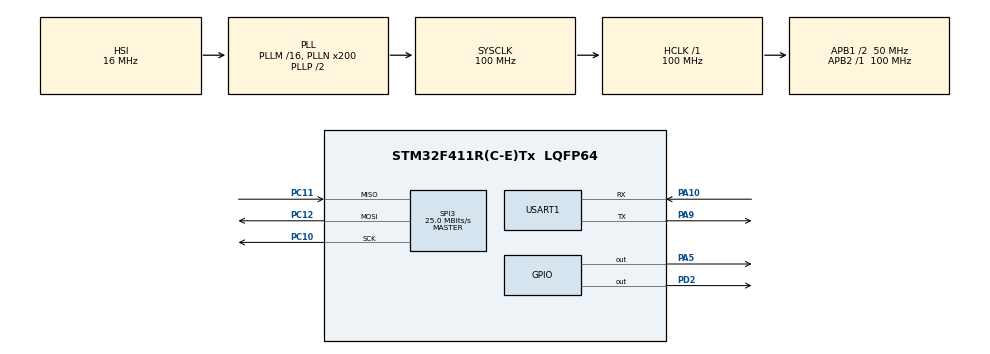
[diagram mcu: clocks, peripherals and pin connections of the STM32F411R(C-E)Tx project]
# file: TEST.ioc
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Mcu.Family=STM32F4
Mcu.Name=STM32F411R(C-E)Tx
Mcu.Package=LQFP64
NVIC.PriorityGroup=NVIC_PRIORITYGROUP_4
PA10.Mode=Asynchronous
PA10.Signal=USART1_RX
PA5.Signal=GPIO_Output
PA9.Mode=Asynchronous
PA9.Signal=USART1_TX
PC10.Mode=Full_Duplex_Master
PC10.Signal=SPI3_SCK
PC11.Mode=Full_Duplex_Master
PC11.Signal=SPI3_MISO
PC12.Mode=Full_Duplex_Master
PC12.Signal=SPI3_MOSI
PD2.PinState=GPIO_PIN_SET
PD2.Signal=GPIO_Output
ProjectManager.HeapSize=0x200
ProjectManager.StackSize=0x400
ProjectManager.TargetToolchain=Makefile
RCC.48MHZClocksFreq_Value=50000000
RCC.AHBFreq_Value=100000000
RCC.APB1CLKDivider=RCC_HCLK_DIV2
RCC.APB1Freq_Value=50000000
RCC.APB1TimFreq_Value=100000000
RCC.APB2Freq_Value=100000000
RCC.APB2TimFreq_Value=100000000
RCC.CortexFreq_Value=100000000
RCC.HCLKFreq_Value=100000000
RCC.HSE_VALUE=25000000
RCC.HSI_VALUE=16000000
RCC.LSE_VALUE=32768
RCC.PLLN=200
RCC.SYSCLKFreq_VALUE=100000000
RCC.SYSCLKSource=RCC_SYSCLKSOURCE_PLLCLK
RCC.VCOOutputFreq_Value=200000000
SPI3.BaudRatePrescaler=SPI_BAUDRATEPRESCALER_2
SPI3.CalculateBaudRate=25.0 MBits/s
SPI3.Direction=SPI_DIRECTION_2LINES
SPI3.Mode=SPI_MODE_MASTER
SPI3.VirtualType=VM_MASTER
USART1.VirtualMode=VM_ASYNC
VP_CRC_VS_CRC.Mode=CRC_Activate
board=custom

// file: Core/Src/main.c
/* USER CODE BEGIN Header */
/**
  ******************************************************************************
  * @file           : main.c
  * @brief          : Main program body
  ******************************************************************************
  * @attention
  *
  * Copyright (c) 2024 STMicroelectronics.
  * All rights reserved.
  *
  * This software is licensed under terms that can be found in the LICENSE file
  * in the root directory of this software component.
  * If no LICENSE file comes with this software, it is provided AS-IS.
  *
  ******************************************************************************
  */
/* USER CODE END Header */
#include "main.h"

/* USER CODE BEGIN PD */
#define MAJOR 0
#define MINOR 1

const uint8_t APP_VERSION[2]={MAJOR,MINOR};
/* USER CODE END PD */

CRC_HandleTypeDef hcrc;

SPI_HandleTypeDef hspi3;

UART_HandleTypeDef huart1;

void SystemClock_Config(void);
static void MX_GPIO_Init(void);
static void MX_CRC_Init(void);
static void MX_SPI3_Init(void);
static void MX_USART1_UART_Init(void);

int main(void)
{

  /* MCU Configuration--------------------------------------------------------*/

  /* Reset of all peripherals, Initializes the Flash interface and the Systick. */
  HAL_Init();

  /* Configure the system clock */
  SystemClock_Config();

  /* Initialize all configured peripherals */
  MX_GPIO_Init();
  MX_CRC_Init();
  MX_SPI3_Init();
  MX_USART1_UART_Init();

  /* Infinite loop */
  while (1)
  {
   HAL_GPIO_WritePin(GPIOA,GPIO_PIN_5,GPIO_PIN_SET); //LED ON
   HAL_Delay(50); //DELAY
   HAL_GPIO_WritePin(GPIOA,GPIO_PIN_5,GPIO_PIN_RESET); //LED OFF
   HAL_Delay(50);
  }
}

void SystemClock_Config(void)
{
  RCC_OscInitTypeDef RCC_OscInitStruct = {0};
  RCC_ClkInitTypeDef RCC_ClkInitStruct = {0};

  /** Configure the main internal regulator output voltage
  */
  __HAL_RCC_PWR_CLK_ENABLE();
  __HAL_PWR_VOLTAGESCALING_CONFIG(PWR_REGULATOR_VOLTAGE_SCALE1);

  /** Initializes the RCC Oscillators according to the specified parameters
  * in the RCC_OscInitTypeDef structure.
  */
  RCC_OscInitStruct.OscillatorType = RCC_OSCILLATORTYPE_HSI;
  RCC_OscInitStruct.HSIState = RCC_HSI_ON;
  RCC_OscInitStruct.HSICalibrationValue = RCC_HSICALIBRATION_DEFAULT;
  RCC_OscInitStruct.PLL.PLLState = RCC_PLL_ON;
  RCC_OscInitStruct.PLL.PLLSource = RCC_PLLSOURCE_HSI;
  RCC_OscInitStruct.PLL.PLLM = 16;
  RCC_OscInitStruct.PLL.PLLN = 200;
  RCC_OscInitStruct.PLL.PLLP = RCC_PLLP_DIV2;
  RCC_OscInitStruct.PLL.PLLQ = 4;
  if (HAL_RCC_OscConfig(&RCC_OscInitStruct) != HAL_OK)
  {
    Error_Handler();
  }

  /** Initializes the CPU, AHB and APB buses clocks
  */
  RCC_ClkInitStruct.ClockType = RCC_CLOCKTYPE_HCLK|RCC_CLOCKTYPE_SYSCLK
                              |RCC_CLOCKTYPE_PCLK1|RCC_CLOCKTYPE_PCLK2;
  RCC_ClkInitStruct.SYSCLKSource = RCC_SYSCLKSOURCE_PLLCLK;
  RCC_ClkInitStruct.AHBCLKDivider = RCC_SYSCLK_DIV1;
  RCC_ClkInitStruct.APB1CLKDivider = RCC_HCLK_DIV2;
  RCC_ClkInitStruct.APB2CLKDivider = RCC_HCLK_DIV1;

  if (HAL_RCC_ClockConfig(&RCC_ClkInitStruct, FLASH_LATENCY_3) != HAL_OK)
  {
    Error_Handler();
  }
}

static void MX_CRC_Init(void)
{

  hcrc.Instance = CRC;
  if (HAL_CRC_Init(&hcrc) != HAL_OK)
  {
    Error_Handler();
  }

}

static void MX_SPI3_Init(void)
{

  /* SPI3 parameter configuration*/
  hspi3.Instance = SPI3;
  hspi3.Init.Mode = SPI_MODE_MASTER;
  hspi3.Init.Direction = SPI_DIRECTION_2LINES;
  hspi3.Init.DataSize = SPI_DATASIZE_8BIT;
  hspi3.Init.CLKPolarity = SPI_POLARITY_LOW;
  hspi3.Init.CLKPhase = SPI_PHASE_1EDGE;
  hspi3.Init.NSS = SPI_NSS_SOFT;
  hspi3.Init.BaudRatePrescaler = SPI_BAUDRATEPRESCALER_2;
  hspi3.Init.FirstBit = SPI_FIRSTBIT_MSB;
  hspi3.Init.TIMode = SPI_TIMODE_DISABLE;
  hspi3.Init.CRCCalculation = SPI_CRCCALCULATION_DISABLE;
  hspi3.Init.CRCPolynomial = 10;
  if (HAL_SPI_Init(&hspi3) != HAL_OK)
  {
    Error_Handler();
  }

}

static void MX_USART1_UART_Init(void)
{

  huart1.Instance = USART1;
  huart1.Init.BaudRate = 115200;
  huart1.Init.WordLength = UART_WORDLENGTH_8B;
  huart1.Init.StopBits = UART_STOPBITS_1;
  huart1.Init.Parity = UART_PARITY_NONE;
  huart1.Init.Mode = UART_MODE_TX_RX;
  huart1.Init.HwFlowCtl = UART_HWCONTROL_NONE;
  huart1.Init.OverSampling = UART_OVERSAMPLING_16;
  if (HAL_UART_Init(&huart1) != HAL_OK)
  {
    Error_Handler();
  }

}

static void MX_GPIO_Init(void)
{
  GPIO_InitTypeDef GPIO_InitStruct = {0};

  /* GPIO Ports Clock Enable */
  __HAL_RCC_GPIOA_CLK_ENABLE();
  __HAL_RCC_GPIOC_CLK_ENABLE();
  __HAL_RCC_GPIOD_CLK_ENABLE();

  /*Configure GPIO pin Output Level */
  HAL_GPIO_WritePin(GPIOA, GPIO_PIN_5, GPIO_PIN_RESET);

  /*Configure GPIO pin Output Level */
  HAL_GPIO_WritePin(GPIOD, GPIO_PIN_2, GPIO_PIN_SET);

  /*Configure GPIO pin : PA5 */
  GPIO_InitStruct.Pin = GPIO_PIN_5;
  GPIO_InitStruct.Mode = GPIO_MODE_OUTPUT_PP;
  GPIO_InitStruct.Pull = GPIO_NOPULL;
  GPIO_InitStruct.Speed = GPIO_SPEED_FREQ_LOW;
  HAL_GPIO_Init(GPIOA, &GPIO_InitStruct);

  /*Configure GPIO pin : PD2 */
  GPIO_InitStruct.Pin = GPIO_PIN_2;
  GPIO_InitStruct.Mode = GPIO_MODE_OUTPUT_PP;
  GPIO_InitStruct.Pull = GPIO_NOPULL;
  GPIO_InitStruct.Speed = GPIO_SPEED_FREQ_LOW;
  HAL_GPIO_Init(GPIOD, &GPIO_InitStruct);

}

void Error_Handler(void)
{
  __disable_irq();
  while (1)
  {
  }
}
